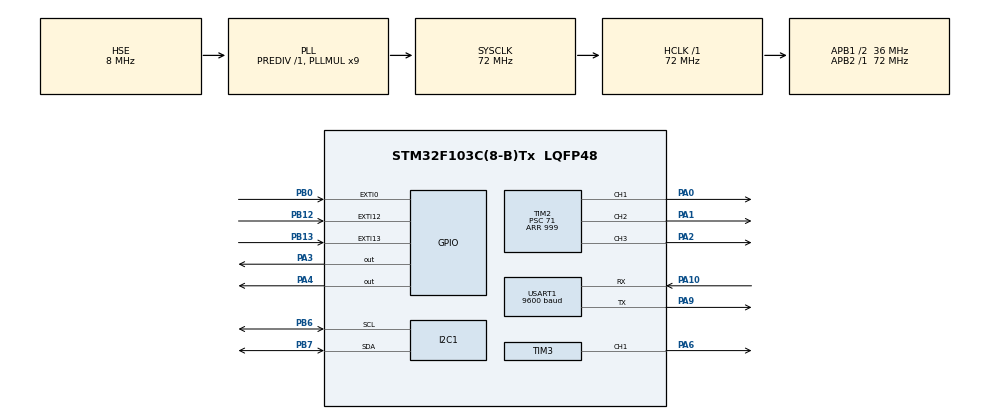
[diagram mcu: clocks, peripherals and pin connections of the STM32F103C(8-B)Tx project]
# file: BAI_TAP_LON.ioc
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FREERTOS.INCLUDE_uxTaskGetStackHighWaterMark=1
FREERTOS.INCLUDE_vTaskDelayUntil=1
FREERTOS.Tasks01=defaultTask,-2,128,StartDefaultTask,Default,NULL,Dynamic,NULL,NULL
FREERTOS.configCHECK_FOR_STACK_OVERFLOW=2
FREERTOS.configTOTAL_HEAP_SIZE=10240
Mcu.Family=STM32F1
Mcu.Name=STM32F103C(8-B)Tx
Mcu.Package=LQFP48
NVIC.EXTI0_IRQn=true\:6\:0\:true\:false\:true\:true\:true\:true\:true
NVIC.EXTI15_10_IRQn=true\:5\:0\:false\:false\:true\:true\:true\:true\:true
NVIC.PriorityGroup=NVIC_PRIORITYGROUP_4
NVIC.TIM4_IRQn=true\:15\:0\:false\:false\:true\:false\:false\:true\:true
NVIC.TimeBase=TIM4_IRQn
NVIC.TimeBaseIP=TIM4
NVIC.USART1_IRQn=true\:6\:0\:true\:false\:true\:true\:true\:true\:true
PA0-WKUP.Signal=S_TIM2_CH1_ETR
PA1.Signal=S_TIM2_CH2
PA10.Mode=Asynchronous
PA10.Signal=USART1_RX
PA13.Mode=Serial_Wire
PA13.Signal=SYS_JTMS-SWDIO
PA14.Mode=Serial_Wire
PA14.Signal=SYS_JTCK-SWCLK
PA2.Signal=S_TIM2_CH3
PA3.Signal=GPIO_Output
PA4.Signal=GPIO_Output
PA6.Signal=S_TIM3_CH1
PA9.Mode=Asynchronous
PA9.Signal=USART1_TX
PB0.GPIO_ModeDefaultEXTI=GPIO_MODE_IT_FALLING
PB0.GPIO_PuPd=GPIO_PULLUP
PB0.Signal=GPXTI0
PB12.GPIO_ModeDefaultEXTI=GPIO_MODE_IT_RISING_FALLING
PB12.Signal=GPXTI12
PB13.GPIO_ModeDefaultEXTI=GPIO_MODE_IT_RISING_FALLING
PB13.Signal=GPXTI13
PB6.Mode=I2C
PB6.Signal=I2C1_SCL
PB7.Mode=I2C
PB7.Signal=I2C1_SDA
PD0-OSC_IN.Mode=HSE-External-Oscillator
PD0-OSC_IN.Signal=RCC_OSC_IN
PD1-OSC_OUT.Mode=HSE-External-Oscillator
PD1-OSC_OUT.Signal=RCC_OSC_OUT
ProjectManager.HeapSize=0x200
ProjectManager.StackSize=0x400
ProjectManager.TargetToolchain=MDK-ARM V5.32
RCC.AHBFreq_Value=72000000
RCC.APB1CLKDivider=RCC_HCLK_DIV2
RCC.APB1Freq_Value=36000000
RCC.APB1TimFreq_Value=72000000
RCC.APB2Freq_Value=72000000
RCC.APB2TimFreq_Value=72000000
RCC.HCLKFreq_Value=72000000
RCC.PLLMUL=RCC_PLL_MUL9
RCC.PLLSourceVirtual=RCC_PLLSOURCE_HSE
RCC.SYSCLKFreq_VALUE=72000000
RCC.SYSCLKSource=RCC_SYSCLKSOURCE_PLLCLK
RCC.USBFreq_Value=72000000
SH.S_TIM2_CH1_ETR.0=TIM2_CH1,PWM Generation1 CH1
SH.S_TIM2_CH2.0=TIM2_CH2,PWM Generation2 CH2
SH.S_TIM2_CH3.0=TIM2_CH3,PWM Generation3 CH3
SH.S_TIM3_CH1.0=TIM3_CH1,PWM Generation1 CH1
TIM2.Channel-PWM\ Generation1\ CH1=TIM_CHANNEL_1
TIM2.Channel-PWM\ Generation2\ CH2=TIM_CHANNEL_2
TIM2.Channel-PWM\ Generation3\ CH3=TIM_CHANNEL_3
TIM2.Period=999
TIM2.Prescaler=71
TIM3.Channel-PWM\ Generation1\ CH1=TIM_CHANNEL_1
TIM3.Period=999
TIM3.Prescaler=71
USART1.BaudRate=9600
USART1.VirtualMode=VM_ASYNC
VP_FREERTOS_VS_CMSIS_V1.Mode=CMSIS_V1
VP_SYS_VS_tim4.Mode=TIM4
board=custom

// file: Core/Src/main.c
/* USER CODE BEGIN Header */
/**
  ******************************************************************************
  * @file           : main.c
  * @brief          : Main program body
  ******************************************************************************
  * @attention
  *
  * Copyright (c) 2026 STMicroelectronics.
  * All rights reserved.
  *
  * This software is licensed under terms that can be found in the LICENSE file
  * in the root directory of this software component.
  * If no LICENSE file comes with this software, it is provided AS-IS.
  *
  ******************************************************************************
  */
/* USER CODE END Header */
#include "main.h"
#include "cmsis_os.h"

/* USER CODE BEGIN Includes */
#include "app_main.h"
/* USER CODE END Includes */

I2C_HandleTypeDef hi2c1;

TIM_HandleTypeDef htim2;
TIM_HandleTypeDef htim3;

UART_HandleTypeDef huart1;

osThreadId defaultTaskHandle;

void SystemClock_Config(void);
static void MX_GPIO_Init(void);
static void MX_I2C1_Init(void);
static void MX_TIM2_Init(void);
static void MX_TIM3_Init(void);
static void MX_USART1_UART_Init(void);
void StartDefaultTask(void const * argument);

int main(void)
{

  /* MCU Configuration--------------------------------------------------------*/

  /* Reset of all peripherals, Initializes the Flash interface and the Systick. */
  HAL_Init();

  /* Configure the system clock */
  SystemClock_Config();

  /* Initialize all configured peripherals */
  MX_GPIO_Init();
  MX_I2C1_Init();
  MX_TIM2_Init();
  MX_TIM3_Init();
  MX_USART1_UART_Init();
  /* USER CODE BEGIN 2 */
  app_hw_init(&hi2c1, &htim2, &htim3, &huart1);
  /* USER CODE END 2 */

  /* Create the thread(s) */
  /* definition and creation of defaultTask */
  osThreadDef(defaultTask, StartDefaultTask, osPriorityLow, 0, 128);
  defaultTaskHandle = osThreadCreate(osThread(defaultTask), NULL);

  /* USER CODE BEGIN RTOS_THREADS */
  /* add threads, ... */
   app_rtos_init();
  /* USER CODE END RTOS_THREADS */

  /* Start scheduler */
  osKernelStart();

  /* We should never get here as control is now taken by the scheduler */

  /* Infinite loop */
  while (1)
  {

  }
}

void SystemClock_Config(void)
{
  RCC_OscInitTypeDef RCC_OscInitStruct = {0};
  RCC_ClkInitTypeDef RCC_ClkInitStruct = {0};

  /** Initializes the RCC Oscillators according to the specified parameters
  * in the RCC_OscInitTypeDef structure.
  */
  RCC_OscInitStruct.OscillatorType = RCC_OSCILLATORTYPE_HSE;
  RCC_OscInitStruct.HSEState = RCC_HSE_ON;
  RCC_OscInitStruct.HSEPredivValue = RCC_HSE_PREDIV_DIV1;
  RCC_OscInitStruct.HSIState = RCC_HSI_ON;
  RCC_OscInitStruct.PLL.PLLState = RCC_PLL_ON;
  RCC_OscInitStruct.PLL.PLLSource = RCC_PLLSOURCE_HSE;
  RCC_OscInitStruct.PLL.PLLMUL = RCC_PLL_MUL9;
  if (HAL_RCC_OscConfig(&RCC_OscInitStruct) != HAL_OK)
  {
    Error_Handler();
  }

  /** Initializes the CPU, AHB and APB buses clocks
  */
  RCC_ClkInitStruct.ClockType = RCC_CLOCKTYPE_HCLK|RCC_CLOCKTYPE_SYSCLK
                              |RCC_CLOCKTYPE_PCLK1|RCC_CLOCKTYPE_PCLK2;
  RCC_ClkInitStruct.SYSCLKSource = RCC_SYSCLKSOURCE_PLLCLK;
  RCC_ClkInitStruct.AHBCLKDivider = RCC_SYSCLK_DIV1;
  RCC_ClkInitStruct.APB1CLKDivider = RCC_HCLK_DIV2;
  RCC_ClkInitStruct.APB2CLKDivider = RCC_HCLK_DIV1;

  if (HAL_RCC_ClockConfig(&RCC_ClkInitStruct, FLASH_LATENCY_2) != HAL_OK)
  {
    Error_Handler();
  }
}

static void MX_I2C1_Init(void)
{

  hi2c1.Instance = I2C1;
  hi2c1.Init.ClockSpeed = 100000;
  hi2c1.Init.DutyCycle = I2C_DUTYCYCLE_2;
  hi2c1.Init.OwnAddress1 = 0;
  hi2c1.Init.AddressingMode = I2C_ADDRESSINGMODE_7BIT;
  hi2c1.Init.DualAddressMode = I2C_DUALADDRESS_DISABLE;
  hi2c1.Init.OwnAddress2 = 0;
  hi2c1.Init.GeneralCallMode = I2C_GENERALCALL_DISABLE;
  hi2c1.Init.NoStretchMode = I2C_NOSTRETCH_DISABLE;
  if (HAL_I2C_Init(&hi2c1) != HAL_OK)
  {
    Error_Handler();
  }

}

static void MX_TIM2_Init(void)
{

  TIM_MasterConfigTypeDef sMasterConfig = {0};
  TIM_OC_InitTypeDef sConfigOC = {0};

  htim2.Instance = TIM2;
  htim2.Init.Prescaler = 71;
  htim2.Init.CounterMode = TIM_COUNTERMODE_UP;
  htim2.Init.Period = 999;
  htim2.Init.ClockDivision = TIM_CLOCKDIVISION_DIV1;
  htim2.Init.AutoReloadPreload = TIM_AUTORELOAD_PRELOAD_DISABLE;
  if (HAL_TIM_PWM_Init(&htim2) != HAL_OK)
  {
    Error_Handler();
  }
  sMasterConfig.MasterOutputTrigger = TIM_TRGO_RESET;
  sMasterConfig.MasterSlaveMode = TIM_MASTERSLAVEMODE_DISABLE;
  if (HAL_TIMEx_MasterConfigSynchronization(&htim2, &sMasterConfig) != HAL_OK)
  {
    Error_Handler();
  }
  sConfigOC.OCMode = TIM_OCMODE_PWM1;
  sConfigOC.Pulse = 0;
  sConfigOC.OCPolarity = TIM_OCPOLARITY_HIGH;
  sConfigOC.OCFastMode = TIM_OCFAST_DISABLE;
  if (HAL_TIM_PWM_ConfigChannel(&htim2, &sConfigOC, TIM_CHANNEL_1) != HAL_OK)
  {
    Error_Handler();
  }
  if (HAL_TIM_PWM_ConfigChannel(&htim2, &sConfigOC, TIM_CHANNEL_2) != HAL_OK)
  {
    Error_Handler();
  }
  if (HAL_TIM_PWM_ConfigChannel(&htim2, &sConfigOC, TIM_CHANNEL_3) != HAL_OK)
  {
    Error_Handler();
  }
  HAL_TIM_MspPostInit(&htim2);

}

static void MX_TIM3_Init(void)
{

  TIM_MasterConfigTypeDef sMasterConfig = {0};
  TIM_OC_InitTypeDef sConfigOC = {0};

  htim3.Instance = TIM3;
  htim3.Init.Prescaler = 71;
  htim3.Init.CounterMode = TIM_COUNTERMODE_UP;
  htim3.Init.Period = 999;
  htim3.Init.ClockDivision = TIM_CLOCKDIVISION_DIV1;
  htim3.Init.AutoReloadPreload = TIM_AUTORELOAD_PRELOAD_DISABLE;
  if (HAL_TIM_PWM_Init(&htim3) != HAL_OK)
  {
    Error_Handler();
  }
  sMasterConfig.MasterOutputTrigger = TIM_TRGO_RESET;
  sMasterConfig.MasterSlaveMode = TIM_MASTERSLAVEMODE_DISABLE;
  if (HAL_TIMEx_MasterConfigSynchronization(&htim3, &sMasterConfig) != HAL_OK)
  {
    Error_Handler();
  }
  sConfigOC.OCMode = TIM_OCMODE_PWM1;
  sConfigOC.Pulse = 0;
  sConfigOC.OCPolarity = TIM_OCPOLARITY_HIGH;
  sConfigOC.OCFastMode = TIM_OCFAST_DISABLE;
  if (HAL_TIM_PWM_ConfigChannel(&htim3, &sConfigOC, TIM_CHANNEL_1) != HAL_OK)
  {
    Error_Handler();
  }
  HAL_TIM_MspPostInit(&htim3);

}

static void MX_USART1_UART_Init(void)
{

  huart1.Instance = USART1;
  huart1.Init.BaudRate = 9600;
  huart1.Init.WordLength = UART_WORDLENGTH_8B;
  huart1.Init.StopBits = UART_STOPBITS_1;
  huart1.Init.Parity = UART_PARITY_NONE;
  huart1.Init.Mode = UART_MODE_TX_RX;
  huart1.Init.HwFlowCtl = UART_HWCONTROL_NONE;
  huart1.Init.OverSampling = UART_OVERSAMPLING_16;
  if (HAL_UART_Init(&huart1) != HAL_OK)
  {
    Error_Handler();
  }

}

static void MX_GPIO_Init(void)
{
  GPIO_InitTypeDef GPIO_InitStruct = {0};

  /* GPIO Ports Clock Enable */
  __HAL_RCC_GPIOD_CLK_ENABLE();
  __HAL_RCC_GPIOA_CLK_ENABLE();
  __HAL_RCC_GPIOB_CLK_ENABLE();

  /*Configure GPIO pin Output Level */
  HAL_GPIO_WritePin(GPIOA, GPIO_PIN_3|GPIO_PIN_4, GPIO_PIN_RESET);

  /*Configure GPIO pins : PA3 PA4 */
  GPIO_InitStruct.Pin = GPIO_PIN_3|GPIO_PIN_4;
  GPIO_InitStruct.Mode = GPIO_MODE_OUTPUT_PP;
  GPIO_InitStruct.Pull = GPIO_NOPULL;
  GPIO_InitStruct.Speed = GPIO_SPEED_FREQ_LOW;
  HAL_GPIO_Init(GPIOA, &GPIO_InitStruct);

  /*Configure GPIO pin : PB0 */
  GPIO_InitStruct.Pin = GPIO_PIN_0;
  GPIO_InitStruct.Mode = GPIO_MODE_IT_FALLING;
  GPIO_InitStruct.Pull = GPIO_PULLUP;
  HAL_GPIO_Init(GPIOB, &GPIO_InitStruct);

  /*Configure GPIO pins : PB12 PB13 */
  GPIO_InitStruct.Pin = GPIO_PIN_12|GPIO_PIN_13;
  GPIO_InitStruct.Mode = GPIO_MODE_IT_RISING_FALLING;
  GPIO_InitStruct.Pull = GPIO_NOPULL;
  HAL_GPIO_Init(GPIOB, &GPIO_InitStruct);

  /* EXTI interrupt init*/
  HAL_NVIC_SetPriority(EXTI0_IRQn, 6, 0);
  HAL_NVIC_EnableIRQ(EXTI0_IRQn);

  HAL_NVIC_SetPriority(EXTI15_10_IRQn, 5, 0);
  HAL_NVIC_EnableIRQ(EXTI15_10_IRQn);

}

void StartDefaultTask(void const * argument)
{
  /* USER CODE BEGIN 5 */
  vTaskDelete(NULL);
  /* Infinite loop */
   for(;;)
  {
    osDelay(1);
  }
  /* USER CODE END 5 */
}

void HAL_TIM_PeriodElapsedCallback(TIM_HandleTypeDef *htim)
{
  if (htim->Instance == TIM4)
  {
    HAL_IncTick();
  }
}

void Error_Handler(void)
{
  __disable_irq();
  while (1)
  {
  }
}

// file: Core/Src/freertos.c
/* USER CODE BEGIN Header */
/**
  ******************************************************************************
  * File Name          : freertos.c
  * Description        : Code for freertos applications
  ******************************************************************************
  * @attention
  *
  * Copyright (c) 2026 STMicroelectronics.
  * All rights reserved.
  *
  * This software is licensed under terms that can be found in the LICENSE file
  * in the root directory of this software component.
  * If no LICENSE file comes with this software, it is provided AS-IS.
  *
  ******************************************************************************
  */
/* USER CODE END Header */

#include "FreeRTOS.h"
#include "task.h"
#include "main.h"

/* USER CODE BEGIN Includes */
#include "app_main.h"
/* USER CODE END Includes */

/* GetIdleTaskMemory prototype (linked to static allocation support) */
void vApplicationGetIdleTaskMemory( StaticTask_t **ppxIdleTaskTCBBuffer, StackType_t **ppxIdleTaskStackBuffer, uint32_t *pulIdleTaskStackSize );

/* Hook prototypes */
void vApplicationStackOverflowHook(xTaskHandle xTask, signed char *pcTaskName);

/* USER CODE BEGIN 4 */
__weak void vApplicationStackOverflowHook(xTaskHandle xTask, signed char *pcTaskName)
{
   /* Run time stack overflow checking is performed if
   configCHECK_FOR_STACK_OVERFLOW is defined to 1 or 2. This hook function is
   called if a stack overflow is detected. */
   app_fatal("STACK OVERFLOW", (const char *)pcTaskName);
}
/* USER CODE END 4 */

/* USER CODE BEGIN GET_IDLE_TASK_MEMORY */
static StaticTask_t xIdleTaskTCBBuffer;
static StackType_t xIdleStack[configMINIMAL_STACK_SIZE];

void vApplicationGetIdleTaskMemory( StaticTask_t **ppxIdleTaskTCBBuffer, StackType_t **ppxIdleTaskStackBuffer, uint32_t *pulIdleTaskStackSize )
{
  *ppxIdleTaskTCBBuffer = &xIdleTaskTCBBuffer;
  *ppxIdleTaskStackBuffer = &xIdleStack[0];
  *pulIdleTaskStackSize = configMINIMAL_STACK_SIZE;
  /* place for user code */
}
/* USER CODE END GET_IDLE_TASK_MEMORY */
